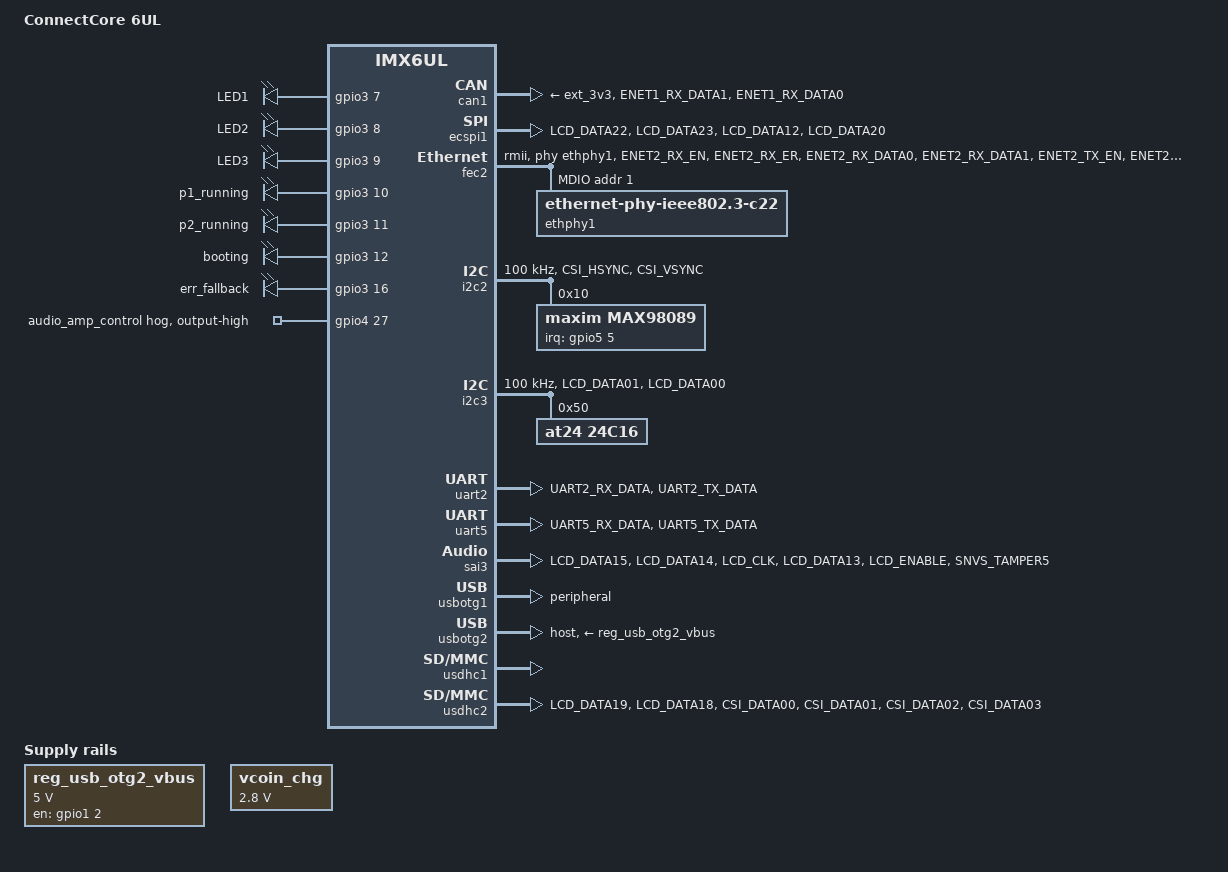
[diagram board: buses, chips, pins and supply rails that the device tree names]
/*
 * Device tree generated automatically by Digi ConnectCore Smart IOmux.
 *
 * This file is provided "AS IS" without any warranties and support.
 * Please verify the pin assignation with the hardware reference manual.
 */

/dts-v1/;

/* i.MX6 UltraLite CPU */
#include "imx6ul.dtsi"
/* ConnectCore 6UL (wireless/bluetooth variant) */
#include "imx6ul-ccimx6ul-wb.dtsi"

/ {
    // Add here your platform model.
    model = "ConnectCore 6UL";

    // Add here your compatible platform.
    compatible = "digi,ccimx6ul", "fsl,imx6ul";

    sound_max98089: sound-max98089 {
		compatible = "fsl,imx-audio-max98088";
		model = "imx-max98088";
		cpu-dai = <&sai3>;
		audio-codec = <&max98089>;
		asrc-controller = <&asrc>;
		gpr = <&gpr>;
		audio-routing =
			"Headphone Jack", "HPL",
			"Headphone Jack", "HPR",
			"Ext Spk", "SPKL",
			"Ext Spk", "SPKR",
			"LineOut", "RECL",
			"LineOut", "RECR",
			"Mic1", "MIC1",
			"Mic2", "MIC2",
			"LineInA", "INA1",
			"LineInA", "INA2",
			"LineInB", "INB1",
			"LineInB", "INB2";
		status = "okay";
	};

	reg_usb_otg2_vbus: reg_usb_otg2@0 {
		compatible = "regulator-fixed";
		pinctrl-names = "default";
		pinctrl-0 = <&pinctrl_usb_otg2_vbus>;
		regulator-name = "usb_otg2_vbus";
		regulator-min-microvolt = <5000000>;
		regulator-max-microvolt = <5000000>;
		gpio = <&gpio1 2 GPIO_ACTIVE_HIGH>;
		enable-active-high;
	};

	leds {
		compatible = "gpio-leds";
		pinctrl-names = "default";
		pinctrl-0 = <&pinctrl_gpio_leds>;

		LED1 {
			gpios = <&gpio3 7 GPIO_ACTIVE_HIGH>;
			default-state = "off";
			linux,default-trigger = "can0-rx";
		};

		LED2 {
			gpios = <&gpio3 8 GPIO_ACTIVE_HIGH>;
			default-state = "off";
		};

		LED3 { // Controlled by hlp_main
			gpios = <&gpio3 9 GPIO_ACTIVE_HIGH>;
			default-state = "off";
		};

		p1_running {
			gpios = <&gpio3 10 GPIO_ACTIVE_HIGH>;
			default-state = "off";
			linux,default-trigger = "heartbeat";
		};

		p2_running {
			gpios = <&gpio3 11 GPIO_ACTIVE_HIGH>;
			default-state = "off";
		};

		booting {
			gpios = <&gpio3 12 GPIO_ACTIVE_HIGH>;
			default-state = "on";
		};

		err_fallback {
			gpios = <&gpio3 16 GPIO_ACTIVE_HIGH>;
			default-state = "off";
			linux,default-trigger = "panic";
		};
	};
};

&gpio1 {
    gpio-line-names = "USB_OTG1_ID","USB_OTG1_OC","USB_HOST_VBUS_ext_ENABLE","USB_HOST_ext_OC_FLAG","USB_OTG1_PWR","HLP_FW_RST_CSP","ETH_MDIO","ETH_MDC", // GPIO1_IO00-GPIO1_IO07
                      "HLP_FW_RST_SUT","HLP_DISCONNECT_SUT","JTAG_MOD","JTAG_TMS","JTAG_TDO","JTAG_TDI","JTAG_TCK","JTAG_TRST_B",                         // GPIO1_IO08-GPIO1_IO15
                      "","","","","UART2_TX","UART2_RX","HLP_FW_RST_OPU","HLP_FW_RST_EXTCAN",                                                             // GPIO1_IO16-GPIO1_IO23
                      "","","","","","","UART5_TX","UART5_RX";                                                                                            // GPIO1_IO24-GPIO1_IO31
};

&gpio3 {
    gpio-line-names = "AUDIO.MCLK","AUDIO.TX_SYNC","DSUB_GPIO11","DSUB_GPIO12","","I2C2_SDA","I2C2_SCL","LED_1",       // GPIO3_IO00-GPIO3_IO07
                      "LED_2","LED_3","P1_running","P2_running","booting","","","",                                    // GPIO3_IO08-GPIO3_IO15
                      "","","AUDIO.TX_BCLK","AUDIO.RX_DATA","AUDIO.TX_DATA","HW_rev_F1","24V_PowerGood","microSD.CMD", // GPIO3_IO16-GPIO3_IO23
                      "microSD.CLK","","HLP_ISO_GPIO_SPARE","HLP_I2C_MUTEX","CSP_I2C_MUTEX","","","";                  // GPIO3_IO24-GPIO3_IO31
};

&gpio4 {
    gpio-line-names = "","","","","","","","", // GPIO4_IO00-GPIO4_IO07
                      "","","","","","","","", // GPIO4_IO08-GPIO4_IO15
                      "","microSD.SD_DET","","I2C1.SDA","I2C1.SCL","microSD.DATA0","microSD.DATA1","microSD.DATA2",  // GPIO4_IO16-GPIO4_IO23
                      "microSD.DATA3","HW_rev_F2","HW_rev_F3","POWER_AMP_CTRL","AUDIO.INT","","","";                 // GPIO4_IO24-GPIO4_IO31

    audio_amp_control {
        gpio-hog;
        gpios = <27 GPIO_ACTIVE_HIGH>;
        output-high; // High = Disable audio amplifier
    };
};

/* Coin cell charging */
&vcoin_chg {
    regulator-min-microvolt = <2800000>;
    regulator-max-microvolt = <2800000>;
    regulator-always-on;
};

&can1 {
    pinctrl-names = "default";
    pinctrl-0 = <&pinctrl_flexcan1>;

    /*
     * Optional field.
     *
     * Set the proper voltage regulator to power the
     * transceiver if needed.
     */
    xceiver-supply = <&ext_3v3>;

    status = "okay";
};

&ecspi1 {
    fsl,spi-num-chipselects = <1>;
    pinctrl-names = "default";
    status = "okay";

    /*
     * ECSPI1 (as master)
     */
    pinctrl-0 = <&pinctrl_ecspi1>;
};

&fec2 {
    pinctrl-names = "default";
    pinctrl-0 = <&pinctrl_enet2 &pinctrl_enet_mdio>;
    phy-mode = "rmii";
    phy-handle = <&ethphy1>;
    phy-reset-gpios = <&mca_gpio 7 GPIO_ACTIVE_LOW>;
    phy-reset-duration = <26>;
    status = "okay";

    mdio {
        #address-cells = <1>;
        #size-cells = <0>;

        ethphy1: ethernet-phy@1 {
            compatible = "ethernet-phy-ieee802.3-c22";
            reg = <1>;
        };
    };
};

&i2c2 {
    clock-frequency = <100000>;
    pinctrl-names = "default";
    pinctrl-0 = <&pinctrl_i2c2>;
    status = "okay";

    max98089: codec@10 {
        compatible = "maxim,max98089";
        reg = <0x10>;
        clocks = <&clks IMX6UL_CLK_SAI3>;
        clock-names = "mclk";
        interrupt-parent = <&gpio5>;
        interrupts = <5 IRQ_TYPE_EDGE_FALLING>;
        status = "okay";
    };
};

&i2c3 {
    clock-frequency = <100000>;
    pinctrl-names = "default";
    pinctrl-0 = <&pinctrl_i2c3>;
    status = "okay";

    at24@50 {
        compatible = "at24,24c16";
        pagesize = <16>;
        reg = <0x50>;
    };
};

&uart2 {
    pinctrl-names = "default";
    pinctrl-0 = <&pinctrl_uart2>;
    status = "okay";
};

&uart5 {
    pinctrl-names = "default";
    pinctrl-0 = <&pinctrl_console>;
    status = "okay";
};

/* SAI3 */
&sai3 {
	pinctrl-names = "default";
	pinctrl-0 = <&pinctrl_sai3>;
	assigned-clocks = <&clks IMX6UL_CLK_SAI3_SEL>,
			  <&clks IMX6UL_CLK_PLL4_AUDIO_DIV>,
			  <&clks IMX6UL_CLK_SAI3>;
	assigned-clock-rates = <0>, <786432000>, <12288000>;
	assigned-clock-parents = <&clks IMX6UL_CLK_PLL4_AUDIO_DIV>;
	fsl,sai-mclk-direction-output;
	status = "okay";
};

&usbotg1 {
    dr_mode = "peripheral";

    /*
     * Set the proper voltage regulator to power the
     * vbus if needed.
     */
    //vbus-supply = <&reg_usb_otg1_vbus>;
    status = "okay";
};

&usbotg2 {
    dr_mode = "host";
    digi,power-line-active-high;
    disable-over-current;
    vbus-supply = <&reg_usb_otg2_vbus>;
    status = "okay";
};

&usdhc1 {
    status = "okay";
};

&usdhc2 {
    pinctrl-names = "default";
    pinctrl-0 = <&pinctrl_usdhc2>;
    no-1-8-v;
    status = "okay";
};

/* Audio chip */
&max98089 {
	status = "okay";
};

&iomuxc {
    pinctrl-0 = <&pinctrl_hog>;

    imx6ul-ccimx6ul {
        pinctrl_console: uart5grp {
            fsl,pins = <
                MX6UL_PAD_UART5_RX_DATA__UART5_DCE_RX		0x1b0b1
                MX6UL_PAD_UART5_TX_DATA__UART5_DCE_TX		0x1b0b1
            >;
        };

        pinctrl_ecspi1: ecspi1grp1 {
            fsl,pins = <
                MX6UL_PAD_LCD_DATA22__ECSPI1_MOSI		0x10b0
                MX6UL_PAD_LCD_DATA23__ECSPI1_MISO		0x10b0
                MX6UL_PAD_LCD_DATA12__ECSPI1_RDY		0x10b0
                MX6UL_PAD_LCD_DATA20__ECSPI1_SCLK		0x10b0
            >;
        };

        pinctrl_enet2: enet2grp {
            fsl,pins = <
                MX6UL_PAD_ENET2_RX_EN__ENET2_RX_EN	0x1b0b0
                MX6UL_PAD_ENET2_RX_ER__ENET2_RX_ER	0x1b0b0
                MX6UL_PAD_ENET2_RX_DATA0__ENET2_RDATA00	0x1b0b0
                MX6UL_PAD_ENET2_RX_DATA1__ENET2_RDATA01	0x1b0b0
                MX6UL_PAD_ENET2_TX_EN__ENET2_TX_EN	0x1b0b0
                MX6UL_PAD_ENET2_TX_DATA0__ENET2_TDATA00	0x1b0b0
                MX6UL_PAD_ENET2_TX_DATA1__ENET2_TDATA01	0x1b0b0
                MX6UL_PAD_ENET2_TX_CLK__ENET2_REF_CLK2	0x40017051
            >;
        };

        pinctrl_enet_mdio: mdioenetgrp {
            fsl,pins = <
                MX6UL_PAD_GPIO1_IO07__ENET2_MDC		0x1b0b0
                MX6UL_PAD_GPIO1_IO06__ENET2_MDIO		0x1b0b0
            >;
        };

        pinctrl_flexcan1: flexcan1grp {
            fsl,pins = <
                MX6UL_PAD_ENET1_RX_DATA1__FLEXCAN1_RX		0x1b020
                MX6UL_PAD_ENET1_RX_DATA0__FLEXCAN1_TX		0x1b020
            >;
        };

        pinctrl_hog: hoggrp {
            fsl,pins = <
                /* GPIO muxed GPIO1 pins */
                MX6UL_PAD_GPIO1_IO00__GPIO1_IO00		0x10b0
                MX6UL_PAD_GPIO1_IO01__GPIO1_IO01		0x10b0
                MX6UL_PAD_GPIO1_IO03__GPIO1_IO03		0x10b0
                MX6UL_PAD_GPIO1_IO04__GPIO1_IO04		0x10b0
                MX6UL_PAD_GPIO1_IO05__GPIO1_IO05		0x10b0
                MX6UL_PAD_GPIO1_IO08__GPIO1_IO08		0x10b0
                MX6UL_PAD_GPIO1_IO09__GPIO1_IO09		0x10b0
                MX6UL_PAD_JTAG_MOD__GPIO1_IO10		    0x10b0
                MX6UL_PAD_JTAG_TMS__GPIO1_IO11		    0x10b0
                MX6UL_PAD_JTAG_TDO__GPIO1_IO12		    0x10b0
                MX6UL_PAD_JTAG_TDI__GPIO1_IO13		    0x10b0
                MX6UL_PAD_JTAG_TCK__GPIO1_IO14		    0x10b0
                MX6UL_PAD_JTAG_TRST_B__GPIO1_IO15		0x10b0
                MX6UL_PAD_UART2_CTS_B__GPIO1_IO22		0x10b0
                MX6UL_PAD_UART2_RTS_B__GPIO1_IO23       0x10b0
                /* GPIO muxed GPIO3 pins */
                MX6UL_PAD_LCD_HSYNC__GPIO3_IO02		    0x10b0
                MX6UL_PAD_LCD_VSYNC__GPIO3_IO03		    0x10b0
                MX6UL_PAD_LCD_DATA20__GPIO3_IO25		0x10b0
                MX6UL_PAD_LCD_DATA21__GPIO3_IO26		0x10b0
                MX6UL_PAD_LCD_DATA22__GPIO3_IO27		0x10b0
                /* GPIO muxed GPIO4 pins */
                MX6UL_PAD_CSI_DATA06__GPIO4_IO27		0x10b0
                /* GPIO muxed GPIO5 pins */
                MX6UL_PAD_SNVS_TAMPER1__GPIO5_IO01		0x10b0
                MX6UL_PAD_SNVS_TAMPER2__GPIO5_IO02		0x10b0
                MX6UL_PAD_SNVS_TAMPER5__GPIO5_IO05		0x10b0
                MX6UL_PAD_SNVS_TAMPER6__GPIO5_IO06		0x10b0
                MX6UL_PAD_SNVS_TAMPER7__GPIO5_IO07		0x10b0
                MX6UL_PAD_SNVS_TAMPER8__GPIO5_IO08		0x10b0
            >;
        };

        pinctrl_i2c2: i2c2grp {
            fsl,pins = <
                MX6UL_PAD_CSI_HSYNC__I2C2_SCL		0x4001b8b0
                MX6UL_PAD_CSI_VSYNC__I2C2_SDA		0x4001b8b0
            >;
        };

        pinctrl_i2c3: i2c3grp {
            fsl,pins = <
                MX6UL_PAD_LCD_DATA01__I2C3_SCL		0x4001b8b0
                MX6UL_PAD_LCD_DATA00__I2C3_SDA		0x4001b8b0
            >;
        };

        pinctrl_uart2: uart2grp {
            fsl,pins = <
                MX6UL_PAD_UART2_RX_DATA__UART2_DCE_RX		0x1b0b1
                MX6UL_PAD_UART2_TX_DATA__UART2_DCE_TX		0x1b0b1
            >;
        };

        pinctrl_usdhc2: usdhc2grp {
            fsl,pins = <
                MX6UL_PAD_LCD_DATA19__USDHC2_CLK		0x10039
                MX6UL_PAD_LCD_DATA18__USDHC2_CMD		0x17059
                MX6UL_PAD_CSI_DATA00__USDHC2_DATA0		0x17059
                MX6UL_PAD_CSI_DATA01__USDHC2_DATA1		0x17059
                MX6UL_PAD_CSI_DATA02__USDHC2_DATA2		0x17059
                MX6UL_PAD_CSI_DATA03__USDHC2_DATA3		0x17059
            >;
        };

        pinctrl_sai3: sai3grp {
            fsl,pins = <
                MX6UL_PAD_LCD_DATA15__SAI3_TX_DATA	0x11088
                MX6UL_PAD_LCD_DATA14__SAI3_RX_DATA	0x11088
                MX6UL_PAD_LCD_CLK__SAI3_MCLK		0x17088
                MX6UL_PAD_LCD_DATA13__SAI3_TX_BCLK	0x17088
                MX6UL_PAD_LCD_ENABLE__SAI3_TX_SYNC	0x17088
                /* Interrupt */
                MX6UL_PAD_SNVS_TAMPER5__GPIO5_IO05	0x80000000
            >;
        };

        pinctrl_usb_otg2_vbus: usbotg2vbusgrp {
            fsl,pins = <
                MX6UL_PAD_GPIO1_IO02__GPIO1_IO02    0x10b0
            >;
        };

        pinctrl_gpio_leds: gpio_leds {
            fsl,pins = <
                MX6UL_PAD_LCD_DATA02__GPIO3_IO07		0x10b0		/* LED1 */
                MX6UL_PAD_LCD_DATA03__GPIO3_IO08		0x10b0		/* LED2 */
                MX6UL_PAD_LCD_DATA04__GPIO3_IO09		0x10b0		/* LED3 */
                MX6UL_PAD_LCD_DATA05__GPIO3_IO10		0x10b0		/* P1_running */
                MX6UL_PAD_LCD_DATA06__GPIO3_IO11		0x10b0		/* P2_running */
                MX6UL_PAD_LCD_DATA07__GPIO3_IO12		0x10b0		/* Booting */
                MX6UL_PAD_LCD_DATA11__GPIO3_IO16		0x10b0		/* Err_fallback */
            >;
        };
    };
};
